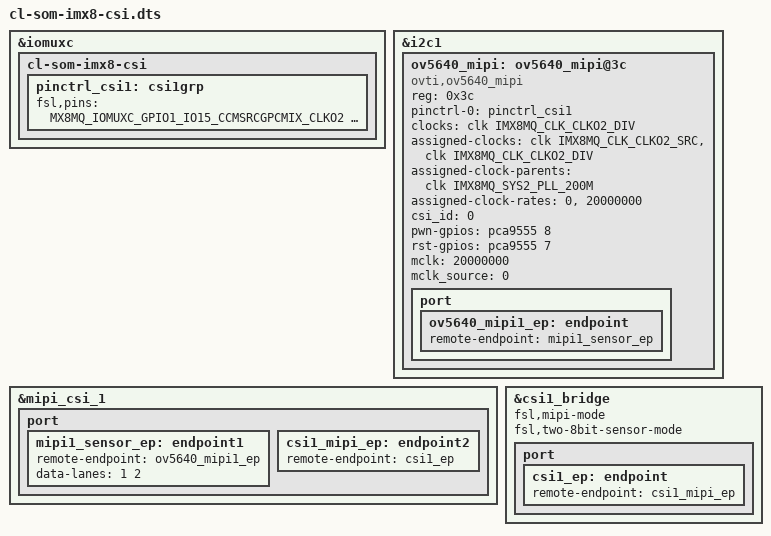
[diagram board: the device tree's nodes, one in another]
/*
 * Copyright (C) 2018 CopuLab Ltd.
 *
 * This program is free software; you can redistribute it and/or
 * modify it under the terms of the GNU General Public License
 * as published by the Free Software Foundation; either version 2
 * of the License, or (at your option) any later version.
 *
 * This program is distributed in the hope that it will be useful,
 * but WITHOUT ANY WARRANTY; without even the implied warranty of
 * MERCHANTABILITY or FITNESS FOR A PARTICULAR PURPOSE.  See the
 * GNU General Public License for more details.
 */

#include "cl-som-imx8.dts"

&iomuxc {
    cl-som-imx8-csi {
        pinctrl_csi1: csi1grp {
            fsl,pins = <
                MX8MQ_IOMUXC_GPIO1_IO15_CCMSRCGPCMIX_CLKO2	0x59
            >;
        };
    };
};

&i2c1 {
    ov5640_mipi: ov5640_mipi@3c {
        compatible = "ovti,ov5640_mipi";
        reg = <0x3c>;
        status = "okay";
        pinctrl-names = "default";
        pinctrl-0 = <&pinctrl_csi1>;
        clocks = <&clk IMX8MQ_CLK_CLKO2_DIV>;
        clock-names = "csi_mclk";
        assigned-clocks = <&clk IMX8MQ_CLK_CLKO2_SRC>,
                  <&clk IMX8MQ_CLK_CLKO2_DIV>;
        assigned-clock-parents = <&clk IMX8MQ_SYS2_PLL_200M>;
        assigned-clock-rates = <0>, <20000000>;
        csi_id = <0>;
        pwn-gpios = <&pca9555 8 GPIO_ACTIVE_HIGH>;
        rst-gpios = <&pca9555 7 GPIO_ACTIVE_HIGH>;
        mclk = <20000000>;
        mclk_source = <0>;
        port {
            ov5640_mipi1_ep: endpoint {
                remote-endpoint = <&mipi1_sensor_ep>;
            };
        };
    };
};

&mipi_csi_1 {
    #address-cells = <1>;
    #size-cells = <0>;
    status = "okay";
    port {
        mipi1_sensor_ep: endpoint1 {
            remote-endpoint = <&ov5640_mipi1_ep>;
            data-lanes = <1 2>;
        };

        csi1_mipi_ep: endpoint2 {
            remote-endpoint = <&csi1_ep>;
        };
    };
};

&csi1_bridge {
    fsl,mipi-mode;
    fsl,two-8bit-sensor-mode;
    status = "okay";

    port {
        csi1_ep: endpoint {
            remote-endpoint = <&csi1_mipi_ep>;
        };
    };
};
